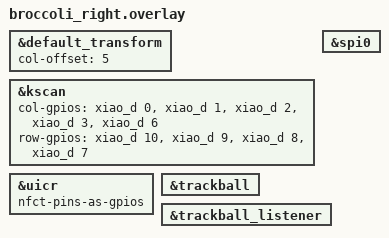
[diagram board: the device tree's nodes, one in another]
// This file was generated from a template. Edit it to match your keyboard.
// See https://zmk.dev/docs/development/hardware-integration/new-shield for more
// instructions.

#include "broccoli.dtsi"

&default_transform {
    // Set this to the number of columns on the left side.
    col-offset = <5>;
};

&kscan {
    // Replace these comments with the GPIO pins in the matrix for the right side.
    // See https://zmk.dev/docs/development/hardware-integration/new-shield#shield-overlays
    col-gpios
        = <&xiao_d 0 GPIO_ACTIVE_HIGH>
        , <&xiao_d 1 GPIO_ACTIVE_HIGH>
        , <&xiao_d 2 GPIO_ACTIVE_HIGH>
        , <&xiao_d 3 GPIO_ACTIVE_HIGH>
        , <&xiao_d 6 GPIO_ACTIVE_HIGH>
        ;
    row-gpios
        = <&xiao_d 10 (GPIO_ACTIVE_HIGH | GPIO_PULL_DOWN)>
        , <&xiao_d 9 (GPIO_ACTIVE_HIGH | GPIO_PULL_DOWN)>
        , <&xiao_d 8 (GPIO_ACTIVE_HIGH | GPIO_PULL_DOWN)>
        , <&xiao_d 7 (GPIO_ACTIVE_HIGH | GPIO_PULL_DOWN)>
        ;
};

&uicr {
    nfct-pins-as-gpios;
};

&spi0 {
    status = "okay";
};

&trackball {
    status = "okay";
};

&trackball_listener {
    status = "okay";
};
